AUTOSAR XML (schema 4-3-0)
package /Impl_SWC_OUTP_ARPkg
  swc implementation Impl_SWC_OUTP_type: programming-language=C, sw-version=1.0.0, vendor-id=0, behavior=SWC_OUTP_type_IB
    code-descriptors:
      code SRC: artifact-descriptors=autosar-engineering-object={short-label=EngObject, category=SWSRC}
    resource consumption ResourceConsumption
      memory section Mem_SWC_OUTP_CAL: size=0, sw-addrmethod=CAL, symbol=CAL
      memory section Mem_SWC_OUTP_CODE: size=0, sw-addrmethod=CODE, symbol=CODE
package /Impl_Type_OUTP_ARPkg
  6 x impl type:
    BOUTP_outputs: category=STRUCTURE
      1177 x element, all with category=TYPE_REFERENCE:
        VOUTP_HVTHCMSysAvail_enum: implementation-data-type=uint8
        VOUTP_LVBattVoltSta_enum: implementation-data-type=uint8
        VOUTP_VehHVPwrAvail4THCM_W: implementation-data-type=float32
        VOUTP_VehSpeed_kph: implementation-data-type=float32
        VOUTP_VehSpeedTimeOut_flg: implementation-data-type=boolean
        VOUTP_FSOffSw_enum: implementation-data-type=uint8
        VOUTP_FSOffSwTimeOut_flg: implementation-data-type=boolean
        VOUTP_ChrgPlugSta_enum: implementation-data-type=uint8
        VOUTP_PASDRMR_cm: implementation-data-type=uint8
        VOUTP_PASDRML_cm: implementation-data-type=uint8
        VOUTP_PASDRCR_cm: implementation-data-type=uint8
        VOUTP_PASDRCL_cm: implementation-data-type=uint8
        VOUTP_PASDFMR_cm: implementation-data-type=uint8
        VOUTP_PASDFML_cm: implementation-data-type=uint8
        VOUTP_PASDFCR_cm: implementation-data-type=uint8
        VOUTP_PASDFCL_cm: implementation-data-type=uint8
        VOUTP_APSDRLR_cm: implementation-data-type=uint16
        VOUTP_APSDRLL_cm: implementation-data-type=uint16
        VOUTP_APSDFLR_cm: implementation-data-type=uint16
        VOUTP_APSDFLL_cm: implementation-data-type=uint16
        VOUTP_PASAFCL_enum: implementation-data-type=uint8
        VOUTP_PASARMR_enum: implementation-data-type=uint8
        VOUTP_PASARML_enum: implementation-data-type=uint8
        VOUTP_PASARCR_enum: implementation-data-type=uint8
        VOUTP_PASARCL_enum: implementation-data-type=uint8
        VOUTP_PASAFMR_enum: implementation-data-type=uint8
        VOUTP_PASAFML_enum: implementation-data-type=uint8
        VOUTP_PASAFCR_enum: implementation-data-type=uint8
        VOUTP_USSStaRMR_flg: implementation-data-type=boolean
        VOUTP_USSStaRML_flg: implementation-data-type=boolean
        VOUTP_USSStaRLR_flg: implementation-data-type=boolean
        VOUTP_USSStaRLL_flg: implementation-data-type=boolean
        VOUTP_USSStaRCR_flg: implementation-data-type=boolean
        VOUTP_USSStaRCL_flg: implementation-data-type=boolean
        VOUTP_USSStaFMR_flg: implementation-data-type=boolean
        VOUTP_USSStaFML_flg: implementation-data-type=boolean
        VOUTP_USSStaFLR_flg: implementation-data-type=boolean
        VOUTP_USSStaFLL_flg: implementation-data-type=boolean
        VOUTP_USSStaFCR_flg: implementation-data-type=boolean
        VOUTP_USSStaFCL_flg: implementation-data-type=boolean
        VOUTP_Chime_enum: implementation-data-type=uint8
        VOUTP_SNSRLayout_enum: implementation-data-type=uint8
        VOUTP_StaFSya_flg: implementation-data-type=boolean
        VOUTP_ModOperation_enum: implementation-data-type=uint8
        VOUTP_BrkPedalPos_pct: implementation-data-type=float32
        VOUTP_BrkPedalPosTimeOut_flg: implementation-data-type=boolean
        VOUTP_LFRawWhlSpeed_kph: implementation-data-type=float32
        VOUTP_LFRawWhlSpeedTimeOut_flg: implementation-data-type=boolean
        VOUTP_RFRawWhlSpeed_kph: implementation-data-type=float32
        VOUTP_RFRawWhlSpeedTimeOut_flg: implementation-data-type=boolean
        VOUTP_LRRawWhlSpeed_kph: implementation-data-type=float32
        VOUTP_LRRawWhlSpeedTimeOut_flg: implementation-data-type=boolean
        VOUTP_RRRawWhlSpeed_kph: implementation-data-type=float32
        VOUTP_RRRawWhlSpeedTimeOut_flg: implementation-data-type=boolean
        VOUTP_LFRawWhlSpeedV_flg: implementation-data-type=boolean
        VOUTP_LFRawWhlSpeedVTimeOut_flg: implementation-data-type=boolean
        VOUTP_RFRawWhlSpeedV_flg: implementation-data-type=boolean
        VOUTP_RFRawWhlSpeedVTimeOut_flg: implementation-data-type=boolean
        VOUTP_LRRawWhlSpeedV_flg: implementation-data-type=boolean
        VOUTP_LRRawWhlSpeedVTimeOut_flg: implementation-data-type=boolean
        VOUTP_RRRawWhlSpeedV_flg: implementation-data-type=boolean
        VOUTP_RRRawWhlSpeedVTimeOut_flg: implementation-data-type=boolean
        VOUTP_LFWhlRotDir_enum: implementation-data-type=uint8
        VOUTP_LFWhlRotDirTimeOut_flg: implementation-data-type=boolean
        VOUTP_RFWhlRotDir_enum: implementation-data-type=uint8
        VOUTP_RFWhlRotDirTimeOut_flg: implementation-data-type=boolean
        VOUTP_LRWhlRotDir_enum: implementation-data-type=uint8
        VOUTP_LRWhlRotDirTimeOut_flg: implementation-data-type=boolean
        VOUTP_RRWhlRotDir_enum: implementation-data-type=uint8
        VOUTP_RRWhlRotDirTimeOut_flg: implementation-data-type=boolean
        VOUTP_LFPulseCountV_flg: implementation-data-type=boolean
        VOUTP_LFPulseCountVTimeOut_flg: implementation-data-type=boolean
        VOUTP_RFPulseCountV_flg: implementation-data-type=boolean
        VOUTP_RFPulseCountVTimeOut_flg: implementation-data-type=boolean
        VOUTP_LRPulseCountV_flg: implementation-data-type=boolean
        VOUTP_LRPulseCountVTimeOut_flg: implementation-data-type=boolean
        VOUTP_RRPulseCountV_flg: implementation-data-type=boolean
        VOUTP_RRPulseCountVTimeOut_flg: implementation-data-type=boolean
        VOUTP_LFPulseCount_enum: implementation-data-type=uint8
        VOUTP_LFPulseCountTimeOut_flg: implementation-data-type=boolean
        VOUTP_RFPulseCount_enum: implementation-data-type=uint8
        VOUTP_RFPulseCountTimeOut_flg: implementation-data-type=boolean
        VOUTP_LRPulseCount_enum: implementation-data-type=uint8
        VOUTP_LRPulseCountTimeOut_flg: implementation-data-type=boolean
        VOUTP_RRPulseCount_enum: implementation-data-type=uint8
        VOUTP_RRPulseCountTimeOut_flg: implementation-data-type=boolean
        VOUTP_ShifterHandleCmd_enum: implementation-data-type=uint8
        VOUTP_ShifterHandleCmdTimeOut_flg: implementation-data-type=boolean
        VOUTP_DriIntend_enum: implementation-data-type=uint8
        VOUTP_DriIntendTimeOut_flg: implementation-data-type=boolean
        VOUTP_EPSAOIControl_enum: implementation-data-type=uint8
        VOUTP_EPSAOIControlTimeOut_flg: implementation-data-type=boolean
        VOUTP_SASAngle_Deg: implementation-data-type=float32
        VOUTP_SASAngleTimeOut_flg: implementation-data-type=boolean
        VOUTP_SASSpeed_degps: implementation-data-type=float32
        VOUTP_SASSpeedTimeOut_flg: implementation-data-type=boolean
        VOUTP_SASSpeedValid_flg: implementation-data-type=boolean
        VOUTP_SASSpeedValidTimeOut_flg: implementation-data-type=boolean
        VOUTP_SASCAL_flg: implementation-data-type=boolean
        VOUTP_SASCALTimeOut_flg: implementation-data-type=boolean
        VOUTP_SASV_flg: implementation-data-type=boolean
        VOUTP_SASVTimeOut_flg: implementation-data-type=boolean
        VOUTP_GRADE_Deg: implementation-data-type=float32
        VOUTP_GRADETimeOut_flg: implementation-data-type=boolean
        VOUTP_YawRate_degps: implementation-data-type=float32
        VOUTP_YawRateTimeOut_flg: implementation-data-type=boolean
        VOUTP_LatAccel_Gps: implementation-data-type=float32
        VOUTP_LatAccelTimeOut_flg: implementation-data-type=boolean
        VOUTP_LongAccel_Gps: implementation-data-type=float32
        VOUTP_LongAccelTimeOut_flg: implementation-data-type=boolean
        VOUTP_MCPressure_bar: implementation-data-type=float32
        VOUTP_MCPressureTimeOut_flg: implementation-data-type=boolean
        VOUTP_YawRateV_flg: implementation-data-type=boolean
        VOUTP_YawRateVTimeOut_flg: implementation-data-type=boolean
        VOUTP_LatAccelV_flg: implementation-data-type=boolean
        VOUTP_LatAccelVTimeOut_flg: implementation-data-type=boolean
        VOUTP_LongAccelV_flg: implementation-data-type=boolean
        VOUTP_LongAccelVTimeOut_flg: implementation-data-type=boolean
        VOUTP_MCPressureV_bar: implementation-data-type=boolean
        VOUTP_MCPressureVTimeOut_flg: implementation-data-type=boolean
        VOUTP_BrkSwSta_flg: implementation-data-type=boolean
        VOUTP_BrkSwStaTimeOut_flg: implementation-data-type=boolean
        VOUTP_BrkSwV_flg: implementation-data-type=boolean
        VOUTP_BrkSwVTimeOut_flg: implementation-data-type=boolean
        VOUTP_ESCStandstill_flg: implementation-data-type=boolean
        VOUTP_ESCStandstillTimeOut_flg: implementation-data-type=boolean
        VOUTP_ESCAPSSta_enum: implementation-data-type=uint8
        VOUTP_ESCAPSStaTimeOut_flg: implementation-data-type=boolean
        VOUTP_EPBExtReleaseAvail_flg: implementation-data-type=boolean
        VOUTP_EPBExtReleaseAvailTimeOut_flg: implementation-data-type=boolean
        VOUTP_EPBExtApplyAvail_flg: implementation-data-type=boolean
        VOUTP_EPBExtApplyAvailTimeOut_flg: implementation-data-type=boolean
        VOUTP_EPBErrSta_enum: implementation-data-type=uint8
        VOUTP_EPBErrStaTimeOut_flg: implementation-data-type=boolean
        VOUTP_EPBSta_enum: implementation-data-type=uint8
        VOUTP_EPBStaTimeOut_flg: implementation-data-type=boolean
        VOUTP_AVMparkingcancel_enum: implementation-data-type=uint8
        VOUTP_AVMparkingcancelTimeOut_flg: implementation-data-type=boolean
        VOUTP_AVMparkingexcute_enum: implementation-data-type=uint8
        VOUTP_AVMparkingexcuteTimeOut_flg: implementation-data-type=boolean
        VOUTP_AVMParkingmode_enum: implementation-data-type=uint8
        VOUTP_AVMParkingmodeTimeOut_flg: implementation-data-type=boolean
        VOUTP_AVMErrSTA_flg: implementation-data-type=boolean
        VOUTP_AVMErrSTATimeOut_flg: implementation-data-type=boolean
        VOUTP_IVIStatus_flg: implementation-data-type=boolean
        VOUTP_IVIStatusTimeOut_flg: implementation-data-type=boolean
        VOUTP_CAASSw_enum: implementation-data-type=uint8
        VOUTP_CAASSwTimeOut_flg: implementation-data-type=boolean
        VOUTP_IVIScreen_enum: implementation-data-type=uint8
        VOUTP_IVIScreenTimeOut_flg: implementation-data-type=boolean
        VOUTP_ABSActive_flg: implementation-data-type=boolean
        VOUTP_ABSActiveTimeOut_flg: implementation-data-type=boolean
        VOUTP_TCSActive_flg: implementation-data-type=boolean
        VOUTP_TCSActiveTimeOut_flg: implementation-data-type=boolean
        VOUTP_DriverSeatBeltCmd_flg: implementation-data-type=boolean
        VOUTP_DriverSeatBeltCmdTimeOut_flg: implementation-data-type=boolean
        VOUTP_APSProgressPCT_pct: implementation-data-type=float32
        VOUTP_APSRQDisplay_enum: implementation-data-type=uint8
        VOUTP_APSSWVer_enum: implementation-data-type=uint8
        VOUTP_APSHWVer_enum: implementation-data-type=uint8
        VOUTP_APSExitCondition_enum: implementation-data-type=uint8
        VOUTP_APSAngleTarget_Deg: implementation-data-type=float32
        VOUTP_APSVRqEPASCtrl_flg: implementation-data-type=boolean
        VOUTP_APSRqEPASCtrl_flg: implementation-data-type=boolean
        VOUTP_CAASSta_enum: implementation-data-type=uint8
        VOUTP_DKCPDkeyAreaRAPSSta_enum: implementation-data-type=uint8
        VOUTP_DKCParkingModeCmd_enum: implementation-data-type=uint8
        VOUTP_PUIDLowPower_flg: implementation-data-type=boolean
        VOUTP_CAASVMCReqA_flg: implementation-data-type=boolean
        VOUTP_APSShiftPosnReq_enum: implementation-data-type=uint8
        VOUTP_APSSpeedCMD_kph: implementation-data-type=float32
        VOUTP_APSVMCReqA_flg: implementation-data-type=boolean
        VOUTP_RAPSBCMLamp_enum: implementation-data-type=uint8
        VOUTP_RAPSBCMLockReq_flg: implementation-data-type=boolean
        VOUTP_APSPwrReq_enum: implementation-data-type=uint8
        VOUTP_RAPSErrWarnSta_enum: implementation-data-type=uint8
        VOUTP_RAPSErrLv1_flg: implementation-data-type=boolean
        VOUTP_IVIUserTakeOverAPSSta_flg: implementation-data-type=boolean
        VOUTP_AntitheftSta_enum: implementation-data-type=uint8
        VOUTP_TailgateRemote_enum: implementation-data-type=uint8
        VOUTP_HornCtrl_flg: implementation-data-type=boolean
        VOUTP_AllDoorSW_flg: implementation-data-type=boolean
        VOUTP_BCMDoorLockSta_flg: implementation-data-type=boolean
        VOUTP_AntitheftSeatFlod_flg: implementation-data-type=boolean
        VOUTP_HoodSW_flg: implementation-data-type=boolean
        VOUTP_TailgateSW_flg: implementation-data-type=boolean
        VOUTP_DrDoorSW_flg: implementation-data-type=boolean
        VOUTP_PsDoorSW_flg: implementation-data-type=boolean
        VOUTP_RLDoorSW_flg: implementation-data-type=boolean
        VOUTP_RRDoorSW_flg: implementation-data-type=boolean
        VOUTP_LockSetting_flg: implementation-data-type=boolean
        VOUTP_FrChargingDoorCtrl_enum: implementation-data-type=uint8
        VOUTP_RrChargingDoorCtrl_enum: implementation-data-type=uint8
        VOUTP_CrashDetd_flg: implementation-data-type=boolean
        VOUTP_CTDCtrl_enum: implementation-data-type=uint8
        VOUTP_DoorLockIND_flg: implementation-data-type=boolean
        VOUTP_CTDLockSW_flg: implementation-data-type=boolean
        VOUTP_Dimmer_pct: implementation-data-type=float32
        VOUTP_DimmerEN_flg: implementation-data-type=boolean
        VOUTP_PosLamp_flg: implementation-data-type=boolean
        VOUTP_LBeam_flg: implementation-data-type=boolean
        VOUTP_HBeam_flg: implementation-data-type=boolean
        VOUTP_RrFogLamp_flg: implementation-data-type=boolean
        VOUTP_BrakeLamp_flg: implementation-data-type=boolean
        VOUTP_ReverseLamp_flg: implementation-data-type=boolean
        VOUTP_LDRL_flg: implementation-data-type=boolean
        VOUTP_RDRL_flg: implementation-data-type=boolean
        VOUTP_LBSD_flg: implementation-data-type=boolean
        VOUTP_RBSD_flg: implementation-data-type=boolean
        VOUTP_HazardSW_flg: implementation-data-type=boolean
        VOUTP_LTurnLP_flg: implementation-data-type=boolean
        VOUTP_RTurnLP_flg: implementation-data-type=boolean
        VOUTP_BCMBuzzerReq_flg: implementation-data-type=boolean
        VOUTP_MirrorCtrl_enum: implementation-data-type=uint8
        VOUTP_MirrorDefog_flg: implementation-data-type=boolean
        VOUTP_RrDefog_flg: implementation-data-type=boolean
        VOUTP_RoomLampH_flg: implementation-data-type=boolean
        VOUTP_RoomLampL_flg: implementation-data-type=boolean
        VOUTP_TrunkRel_flg: implementation-data-type=boolean
        VOUTP_TailgateHDSW_flg: implementation-data-type=boolean
        VOUTP_FrWiperL_flg: implementation-data-type=boolean
        VOUTP_FrWiperH_flg: implementation-data-type=boolean
        VOUTP_RrWiper_flg: implementation-data-type=boolean
        VOUTP_WasherCtrl_enum: implementation-data-type=uint8
        VOUTP_WiperFixMode_flg: implementation-data-type=boolean
        VOUTP_AmbLightBreath{1..6}_enum: implementation-data-type=uint8
        VOUTP_AmbLightBrightness{1..6}_enum: implementation-data-type=uint8
        VOUTP_AmbLightColor{1..6}_enum: implementation-data-type=uint8
        VOUTP_LampPwr_flg: implementation-data-type=boolean
        VOUTP_SPTGDet_flg: implementation-data-type=boolean
        VOUTP_APSOpenPTG_flg: implementation-data-type=boolean
        VOUTP_FollowMe_flg: implementation-data-type=boolean
        VOUTP_IVIRST_flg: implementation-data-type=boolean
        VOUTP_CountAlarm_enum: implementation-data-type=uint8
        VOUTP_MFSWTri_flg: implementation-data-type=boolean
        VOUTP_MirrorFlodPos_flg: implementation-data-type=boolean
        VOUTP_FuelDoorPos_flg: implementation-data-type=boolean
        VOUTP_MFRDNBrightReq_pct: implementation-data-type=uint8
        VOUTP_PTGInnerSW2_enum: implementation-data-type=uint8
        VOUTP_DrvWdwCtrlCmd_pct: implementation-data-type=uint8
        VOUTP_PasWdwCtrlCmd_pct: implementation-data-type=uint8
        VOUTP_DrRWdwCtrlCmd_pct: implementation-data-type=uint8
        VOUTP_PsRWdwCtrlCmd_pct: implementation-data-type=uint8
        VOUTP_APMDoorControlSta_flg: implementation-data-type=boolean
        VOUTP_AmbFunEN_flg: implementation-data-type=boolean
        VOUTP_AmbWelEN_flg: implementation-data-type=boolean
        VOUTP_AmbDimEN_flg: implementation-data-type=boolean
        VOUTP_AmbLinkDriSta_flg: implementation-data-type=boolean
        VOUTP_AmbPwrWarnEN_flg: implementation-data-type=boolean
        VOUTP_AmbODAEN_flg: implementation-data-type=boolean
        VOUTP_AmbColorSta_enum: implementation-data-type=uint8
        VOUTP_AmbBrightSta_enum: implementation-data-type=uint8
        VOUTP_LockAlarm_enum: implementation-data-type=uint8
        VOUTP_ATCtrl_enum: implementation-data-type=uint8
        VOUTP_fUnlockSingle_flg: implementation-data-type=boolean
        VOUTP_UserNow_enum: implementation-data-type=uint8
        VOUTP_AmbFunENFlash_enum: implementation-data-type=uint8
        VOUTP_AmbWelENFlash_enum: implementation-data-type=uint8
        VOUTP_AmbDimENFlash_enum: implementation-data-type=uint8
        VOUTP_AmbLinkDriStaFlash_enum: implementation-data-type=uint8
        VOUTP_AmbPwrWarnENFlash_enum: implementation-data-type=uint8
        VOUTP_AmbODAENFlash_enum: implementation-data-type=uint8
        VOUTP_AmbColorSta{1..5}_enum: implementation-data-type=uint8
        VOUTP_AmbColorSta7_enum: implementation-data-type=uint8
        VOUTP_AmbBrightnessSta{1..5}_enum: implementation-data-type=uint8
        VOUTP_AmbBrightnessSta7_enum: implementation-data-type=uint8
        VOUTP_HazardIND_flg: implementation-data-type=boolean
        VOUTP_DimSwSta_flg: implementation-data-type=boolean
        VOUTP_PassSWSta_flg: implementation-data-type=boolean
        VOUTP_FWipSwSta_enum: implementation-data-type=uint8
        VOUTP_FWasSwSta_enum: implementation-data-type=uint8
        VOUTP_TurnSwSta_enum: implementation-data-type=uint8
        VOUTP_TurnSwTSetSta_enum: implementation-data-type=uint8
        VOUTP_SPTGENFun_flg: implementation-data-type=boolean
        VOUTP_SPTGENFunMem_enum: implementation-data-type=uint8
        VOUTP_OutMode_enum: implementation-data-type=uint8
        VOUTP_TurnSwTimeSetSta123_enum: implementation-data-type=uint8
        VOUTP_TurnSwTimeSetSta457_enum: implementation-data-type=uint8
        VOUTP_FDLHandleLampCmd_flg: implementation-data-type=boolean
        VOUTP_FDRHandleLampCmd_flg: implementation-data-type=boolean
        VOUTP_FDHandleCmd_enum: implementation-data-type=uint8
        VOUTP_HBeamADB_enum: implementation-data-type=uint8
        VOUTP_WalkInUnLkENMem_enum: implementation-data-type=uint8
        VOUTP_WalkOutLkENMem_enum: implementation-data-type=uint8
        VOUTP_RmLpModeENMem_enum: implementation-data-type=uint8
        VOUTP_LockSettingStaMem_enum: implementation-data-type=uint8
        VOUTP_FollowMeENMem_enum: implementation-data-type=uint8
        VOUTP_WalkInUnLkENFunSta_flg: implementation-data-type=boolean
        VOUTP_WalkOutLkENFunSta_flg: implementation-data-type=boolean
        VOUTP_RmLpModeENFunSta_flg: implementation-data-type=boolean
        VOUTP_FollowMeENFunSta_flg: implementation-data-type=boolean
        VOUTP_HoodRelCmd_flg: implementation-data-type=boolean
        VOUTP_WelcomeLight_enum: implementation-data-type=uint8
        VOUTP_PTGOpenHeightSta_enum: implementation-data-type=uint8
        VOUTP_UserHeightSet_cnt: implementation-data-type=uint16
        VOUTP_PTGUserHeight{1..5}_cnt: implementation-data-type=uint16
        VOUTP_PTGUserHeight7_cnt: implementation-data-type=uint16
        VOUTP_PTGOpenHeight12_enum: implementation-data-type=uint8
        VOUTP_PTGOpenHeight34_enum: implementation-data-type=uint8
        VOUTP_PTGOpenHeight57_enum: implementation-data-type=uint8
        VOUTP_SenstivityPosnCmd_enum: implementation-data-type=uint8
        VOUTP_TimeGapLevelSta_enum: implementation-data-type=uint8
        VOUTP_ACCLevelMem12_enum: implementation-data-type=uint8
        VOUTP_ACCLevelMem34_enum: implementation-data-type=uint8
        VOUTP_ACCLevelMem57_enum: implementation-data-type=uint8
        VOUTP_LRightStaCmd_flg: implementation-data-type=boolean
        VOUTP_LLeftStaCmd_flg: implementation-data-type=boolean
        VOUTP_AutoLockSta_flg: implementation-data-type=boolean
        VOUTP_AutoLockMem_enum: implementation-data-type=uint8
        VOUTP_AutoUnlockSta_flg: implementation-data-type=boolean
        VOUTP_AutoUnlockMem_enum: implementation-data-type=uint8
        VOUTP_HMIKey{1..8}FuncSta_enum: implementation-data-type=uint8
        VOUTP_AutoWipHSpdENSta_flg: implementation-data-type=boolean
        VOUTP_DrvWdwReqAP_enum: implementation-data-type=uint8
        VOUTP_PasWdwReqAP_enum: implementation-data-type=uint8
        VOUTP_DrRWdwReqAP_enum: implementation-data-type=uint8
        VOUTP_PsRWdwReqAP_enum: implementation-data-type=uint8
        VOUTP_CLWinLockDrSta_flg: implementation-data-type=boolean
        VOUTP_CLWinLockDrStaMem_enum: implementation-data-type=uint8
        VOUTP_WinLFOpenedSta_pct: implementation-data-type=uint8
        VOUTP_WinRFOpenedSta_pct: implementation-data-type=uint8
        VOUTP_WinLROpenedSta_pct: implementation-data-type=uint8
        VOUTP_WinRROpenedSta_pct: implementation-data-type=uint8
        VOUTP_C3BMS6RCDTC_raw32: implementation-data-type=uint32
        VOUTP_C3BMS6CSDTC_raw32: implementation-data-type=uint32
        VOUTP_C3BMS6LCDTC_raw32: implementation-data-type=uint32
        VOUTP_C3BMS1RCDTC_raw32: implementation-data-type=uint32
        VOUTP_C3BMS1CSDTC_raw32: implementation-data-type=uint32
        VOUTP_C3BMS1LCDTC_raw32: implementation-data-type=uint32
        VOUTP_C3CCU1RCDTC_raw32: implementation-data-type=uint32
        VOUTP_C3CCU1CSDTC_raw32: implementation-data-type=uint32
        VOUTP_C3CCU1LCDTC_raw32: implementation-data-type=uint32
        VOUTP_C3CCU2RCDTC_raw32: implementation-data-type=uint32
        VOUTP_C3CCU2CSDTC_raw32: implementation-data-type=uint32
        VOUTP_C3CCU2LCDTC_raw32: implementation-data-type=uint32
        VOUTP_C1ABM1RCDTC_raw32: implementation-data-type=uint32
        VOUTP_C1ABM1CSDTC_raw32: implementation-data-type=uint32
        VOUTP_C1ABM1LCDTC_raw32: implementation-data-type=uint32
        VOUTP_Lv{1..4}ErrDTC_raw32: implementation-data-type=uint32
        VOUTP_BrkSWErrDTC_raw32: implementation-data-type=uint32
        VOUTP_BrkSWNoBacDTC_raw32: implementation-data-type=uint32
        VOUTP_KeyAuthDTC_raw32: implementation-data-type=uint32
        VOUTP_ONtoRdyDTC_raw32: implementation-data-type=uint32
        VOUTP_HVB4PreDTC_raw32: implementation-data-type=uint32
        VOUTP_MCU4PreDTC_raw32: implementation-data-type=uint32
        VOUTP_DCDC4PreDTC_raw32: implementation-data-type=uint32
        VOUTP_HVRlyCloDTC_raw32: implementation-data-type=uint32
        VOUTP_BMSRdyDTC_raw32: implementation-data-type=uint32
        VOUTP_DCDCEnaDTC_raw32: implementation-data-type=uint32
        VOUTP_HiLvSaChkDTC_raw32: implementation-data-type=uint32
        VOUTP_MidLvSaChkDTC_raw32: implementation-data-type=uint32
        VOUTP_MCUDisDTC_raw32: implementation-data-type=uint32
        VOUTP_DCDCDisDTC_raw32: implementation-data-type=uint32
        VOUTP_HVRlyOpDTC_raw32: implementation-data-type=uint32
        VOUTP_MCUActDTC_raw32: implementation-data-type=uint32
        VOUTP_OBC4PreDTC_raw32: implementation-data-type=uint32
        VOUTP_IniLVLoDTC_raw32: implementation-data-type=uint32
        VOUTP_LVSupLoDTC_raw32: implementation-data-type=uint32
        VOUTP_LVSupHiDTC_raw32: implementation-data-type=uint32
        VOUTP_DrStSWDTC_raw32: implementation-data-type=uint32
        VOUTP_FLDoorSWDTC_raw32: implementation-data-type=uint32
        VOUTP_RLDoorSWDTC_raw32: implementation-data-type=uint32
        VOUTP_FRDoorSWDTC_raw32: implementation-data-type=uint32
        VOUTP_RRDoorSWDTC_raw32: implementation-data-type=uint32
        VOUTP_HoodSWDTC_raw32: implementation-data-type=uint32
        VOUTP_TailgaSWDTC_raw32: implementation-data-type=uint32
        VOUTP_EDriveSysErrVCUErr_flg: implementation-data-type=boolean
        VOUTP_VehMalfunLevel_enum: implementation-data-type=uint8
        VOUTP_APS1SigOoRDTC_raw32: implementation-data-type=uint32
        VOUTP_APS2SigOoRDTC_raw32: implementation-data-type=uint32
        VOUTP_APSCorrErrDTC_raw32: implementation-data-type=uint32
        VOUTP_MCUF1NoComDTC_raw32: implementation-data-type=uint32
        VOUTP_MCUR1NoComDTC_raw32: implementation-data-type=uint32
        VOUTP_Shifter1NoComDTC_raw32: implementation-data-type=uint32
        VOUTP_ESC7NoComDTC_raw32: implementation-data-type=uint32
        VOUTP_ESC1NoComDTC_raw32: implementation-data-type=uint32
        VOUTP_ESC5NoComDTC_raw32: implementation-data-type=uint32
        VOUTP_EnterNewOperCyc_flg: implementation-data-type=boolean
        VOUTP_DiagHCrashDTC_raw32: implementation-data-type=uint32
        VOUTP_DiagFLTSDTC_raw32: implementation-data-type=uint32
        VOUTP_DiagFRTSDTC_raw32: implementation-data-type=uint32
        VOUTP_DiagRLTSDTC_raw32: implementation-data-type=uint32
        VOUTP_DiagRRTSDTC_raw32: implementation-data-type=uint32
        VOUTP_FCLUSSDTC_raw32: implementation-data-type=uint32
        VOUTP_FMLUSSDTC_raw32: implementation-data-type=uint32
        VOUTP_FMRUSSDTC_raw32: implementation-data-type=uint32
        VOUTP_FCRUSSDTC_raw32: implementation-data-type=uint32
        VOUTP_RCLUSSDTC_raw32: implementation-data-type=uint32
        VOUTP_RMLUSSDTC_raw32: implementation-data-type=uint32
        VOUTP_RMRUSSDTC_raw32: implementation-data-type=uint32
        VOUTP_RCRUSSDTC_raw32: implementation-data-type=uint32
        VOUTP_FLLUSSDTC_raw32: implementation-data-type=uint32
        VOUTP_FLRUSSDTC_raw32: implementation-data-type=uint32
        VOUTP_RLLUSSDTC_raw32: implementation-data-type=uint32
        VOUTP_RLRUSSDTC_raw32: implementation-data-type=uint32
        VOUTP_FCM2NoComDTC_raw32: implementation-data-type=uint32
        VOUTP_FCM2RCErrDTC_raw32: implementation-data-type=uint32
        VOUTP_FCM2CSErrDTC_raw32: implementation-data-type=uint32
        VOUTP_FCM3NoComDTC_raw32: implementation-data-type=uint32
        VOUTP_FCM3RCErrDTC_raw32: implementation-data-type=uint32
        VOUTP_FCM3CSErrDTC_raw32: implementation-data-type=uint32
        VOUTP_FCM4NoComDTC_raw32: implementation-data-type=uint32
        VOUTP_FCM4CSErrDTC_raw32: implementation-data-type=uint32
        VOUTP_FCM5NoComDTC_raw32: implementation-data-type=uint32
        VOUTP_FCM5CSErrDTC_raw32: implementation-data-type=uint32
        VOUTP_ZoneSCPNoComDTC_raw32: implementation-data-type=uint32
        VOUTP_BMSSigErrDetDTC_raw32: implementation-data-type=uint32
        VOUTP_FCMACCSigErrDetDTC_raw32: implementation-data-type=uint32
        VOUTP_FrMCUSigErrDetDTC_raw32: implementation-data-type=uint32
        VOUTP_RrMCUSigErrDetDTC_raw32: implementation-data-type=uint32
        VOUTP_CCUSigErrDetDTC_raw32: implementation-data-type=uint32
        VOUTP_ACCAccelCmdErrDetDTC_raw32: implementation-data-type=uint32
        VOUTP_ACCMalfuncDetDTC_raw32: implementation-data-type=uint32
        VOUTP_CCMalfuncDetDTC_raw32: implementation-data-type=uint32
        VOUTP_MSAMalfuncDetDTC_raw32: implementation-data-type=uint32
        VOUTP_ISAMalfuncDetDTC_raw32: implementation-data-type=uint32
        VOUTP_MCUF1RCErrDTC_raw32: implementation-data-type=uint32
        VOUTP_MCUR1RCErrDTC_raw32: implementation-data-type=uint32
        VOUTP_MCUF1CSErrDTC_raw32: implementation-data-type=uint32
        VOUTP_MCUR1CSErrDTC_raw32: implementation-data-type=uint32
        VOUTP_Shifter1RCErrDTC_raw32: implementation-data-type=uint32
        VOUTP_Shifter1CSErrDTC_raw32: implementation-data-type=uint32
        VOUTP_ESC7RCErrDTC_raw32: implementation-data-type=uint32
        VOUTP_ESC7CSErrDTC_raw32: implementation-data-type=uint32
        VOUTP_ESC1RCErrDTC_raw32: implementation-data-type=uint32
        VOUTP_ESC1CSErrDTC_raw32: implementation-data-type=uint32
        VOUTP_ESC5RCErrDTC_raw32: implementation-data-type=uint32
        VOUTP_ESC5CSErrDTC_raw32: implementation-data-type=uint32
        VOUTP_FrMCUTqErrDTC_raw32: implementation-data-type=uint32
        VOUTP_RrMCUTqErrDTC_raw32: implementation-data-type=uint32
        VOUTP_LFBatwarnDTC_raw32: implementation-data-type=uint32
        VOUTP_RFBatwarnDTC_raw32: implementation-data-type=uint32
        VOUTP_LRBatwarnDTC_raw32: implementation-data-type=uint32
        VOUTP_RRBatwarnDTC_raw32: implementation-data-type=uint32
        VOUTP_LFPressIndiDTC_raw32: implementation-data-type=uint32
        VOUTP_RFPressIndiDTC_raw32: implementation-data-type=uint32
        VOUTP_LRPressIndiDTC_raw32: implementation-data-type=uint32
        VOUTP_RRPressIndiDTC_raw32: implementation-data-type=uint32
        VOUTP_LFWheelTmpHighDTC_raw32: implementation-data-type=uint32
        VOUTP_RFWheelTmpHighDTC_raw32: implementation-data-type=uint32
        VOUTP_LRWheelTmpHighDTC_raw32: implementation-data-type=uint32
        VOUTP_RRWheelTmpHighDTC_raw32: implementation-data-type=uint32
        VOUTP_LFSensorFailDTC_raw32: implementation-data-type=uint32
        VOUTP_RFSensorFailDTC_raw32: implementation-data-type=uint32
        VOUTP_LRSensorFailDTC_raw32: implementation-data-type=uint32
        VOUTP_RRSensorFailDTC_raw32: implementation-data-type=uint32
        VOUTP_C1EPAS2LCDTC_raw32: implementation-data-type=uint32
        VOUTP_5vAPS1PwrErrDTC_raw32: implementation-data-type=uint32
        VOUTP_5vAPS2PwrErrDTC_raw32: implementation-data-type=uint32
        VOUTP_EPBLockTODTC_raw32: implementation-data-type=uint32
        VOUTP_EPBUnlockTODTC_raw32: implementation-data-type=uint32
        VOUTP_LimpHomeAct_flg: implementation-data-type=boolean
        VOUTP_DTCDetect_enum: implementation-data-type=uint8
        VOUTP_EngagePFail_flg: implementation-data-type=boolean
        VOUTP_DisengagePFail_flg: implementation-data-type=boolean
        VOUTP_VCURAPSErrLv2_flg: implementation-data-type=boolean
        VOUTP_VCURAPSErrLv3_flg: implementation-data-type=boolean
        VOUTP_EDriveSysErrShifterErr_flg: implementation-data-type=boolean
        VOUTP_LVSysErrPwrOutErr_flg: implementation-data-type=boolean
        VOUTP_HVRlyOpFail_flg: implementation-data-type=boolean
        VOUTP_MCUActDisFail_flg: implementation-data-type=boolean
        VOUTP_VCUBrkSWSta_enum: implementation-data-type=uint8
        VOUTP_VCUFLDoorSta_flg: implementation-data-type=boolean
        VOUTP_VCUFRDoorSta_flg: implementation-data-type=boolean
        VOUTP_VCURLDoorSta_flg: implementation-data-type=boolean
        VOUTP_VCURRDoorSta_flg: implementation-data-type=boolean
        VOUTP_SysAllowReadySta_flg: implementation-data-type=boolean
        VOUTP_VCUHoodSWSta_flg: implementation-data-type=boolean
        VOUTP_VCUTailgateSWSta_flg: implementation-data-type=boolean
        VOUTP_CAN{1..6}BusErrorDTC_raw32: implementation-data-type=uint32
        VOUTP_FrMCU4PreDTC_raw32: implementation-data-type=uint32
        VOUTP_FrMCUDisDTC_raw32: implementation-data-type=uint32
        VOUTP_FrMCUActDTC_raw32: implementation-data-type=uint32
        VOUTP_RegenErrDTC_raw32: implementation-data-type=uint32
        VOUTP_ActAPSPosn_pct: implementation-data-type=float32
        VOUTP_LowIdleAccPedal_flg: implementation-data-type=boolean
        VOUTP_EAPS1MIN_pct: implementation-data-type=float32
        VOUTP_EAPS2MIN_pct: implementation-data-type=float32
        VOUTP_ResetPedalZeroPosStart_flg: implementation-data-type=boolean
        VOUTP_EAPS1NRM_pct: implementation-data-type=float32
        VOUTP_EAPS2NRM_pct: implementation-data-type=float32
        VOUTP_EAPS1RAW_pct: implementation-data-type=float32
        VOUTP_EAPS2RAW_pct: implementation-data-type=float32
        VOUTP_VSS_kph: implementation-data-type=float32
        VOUTP_RUNTM_s: implementation-data-type=uint16
        VOUTP_MILDIST_km: implementation-data-type=float32
        VOUTP_CLRDIST_km: implementation-data-type=float32
        VOUTP_APPD_pct: implementation-data-type=float32
        VOUTP_APPE_pct: implementation-data-type=float32
        VOUTP_ODOMETER_km: implementation-data-type=float32
        VOUTP_NUMPSATRIPSFLTMEMCLR_cnt: implementation-data-type=uint16
        VOUTP_PSAR_sec: implementation-data-type=uint32
        VOUTP_PSAL_sec: implementation-data-type=uint32
        VOUTP_IPSAR_sec: implementation-data-type=uint32
        VOUTP_IPSAL_sec: implementation-data-type=uint32
        VOUTP_CPSAR_sec: implementation-data-type=uint32
        VOUTP_CPSAL_sec: implementation-data-type=uint32
        VOUTP_PKER_kphsqr: implementation-data-type=float32
        VOUTP_PKEL_kphsqr: implementation-data-type=float32
        VOUTP_ResetCDEODTR_km: implementation-data-type=float32
        VOUTP_CDEODTR_km: implementation-data-type=float32
        VOUTP_CDEODTL_km: implementation-data-type=float32
        VOUTP_QTYPSATRIPSR_cnt: implementation-data-type=uint32
        VOUTP_QTYPSATRIPSL_cnt: implementation-data-type=uint32
        VOUTP_PROTOCOLID_enum: implementation-data-type=uint8
        VOUTP_CALID_cnt: implementation-data-type=u8_Array16_type
        VOUTP_ECUNAME_cnt: implementation-data-type=u8_Array20_type
        VOUTP_PKERNumerator_kphsqr: implementation-data-type=float32
        VOUTP_PKELNumerator_kphsqr: implementation-data-type=float32
        VOUTP_VinCode_cnt: implementation-data-type=u8_Array17_type
        VOUTP_DIDModelVersion_raw: implementation-data-type=uint8
        VOUTP_DIDModelVersionChksum_raw: implementation-data-type=uint8
        VOUTP_DKCTimeSN_cnt: implementation-data-type=uint32
        VOUTP_DKCAuthSta_enum: implementation-data-type=uint8
        VOUTP_TimeSNDKCFbk_cnt: implementation-data-type=uint32
        VOUTP_PCommandToBCM_enum: implementation-data-type=uint8
        VOUTP_KeyAreaLockUnlock_enum: implementation-data-type=uint8
        VOUTP_KeyMissSta_flg: implementation-data-type=boolean
        VOUTP_ShippingMode_flg: implementation-data-type=boolean
        VOUTP_KeyNumSta_enum: implementation-data-type=uint8
        VOUTP_DkeyShowIVISta_enum: implementation-data-type=uint8
        VOUTP_DkeyAreaRAPSSta_enum: implementation-data-type=uint8
        VOUTP_KeyAreaPS_enum: implementation-data-type=uint8
        VOUTP_KeyAreaSPTGSta_enum: implementation-data-type=uint8
        VOUTP_KeyAreaPTG_enum: implementation-data-type=uint8
        VOUTP_UWB4Invalid_flg: implementation-data-type=uint8
        VOUTP_UWBOnOff_flg: implementation-data-type=boolean
        VOUTP_UWB3Invalid_flg: implementation-data-type=uint8
        VOUTP_UWB1Invalid_flg: implementation-data-type=uint8
        VOUTP_UWB2Invalid_flg: implementation-data-type=uint8
        VOUTP_UWB0Invalid_flg: implementation-data-type=uint8
        VOUTP_UIDBatVolt_enum: implementation-data-type=uint16
        VOUTP_CoordinateX_enum: implementation-data-type=sint16
        VOUTP_FDCSPTGDet_flg: implementation-data-type=boolean
        VOUTP_FDCSPTGOpen_flg: implementation-data-type=boolean
        VOUTP_UIDLowPowerSta_flg: implementation-data-type=boolean
        VOUTP_CoordinateY_enum: implementation-data-type=sint16
        VOUTP_AllowSleep_flg: implementation-data-type=boolean
        VOUTP_KeyTypeSta_enum: implementation-data-type=uint8
        VOUTP_CalDistance_enum: implementation-data-type=uint8
        VOUTP_UWBDetPTGArea_enum: implementation-data-type=uint8
        VOUTP_A0UWBEvent_enum: implementation-data-type=uint8
        VOUTP_ParkingModeCmd_enum: implementation-data-type=uint8
        VOUTP_KeyModeSta_enum: implementation-data-type=uint8
        VOUTP_ReVehData_enum: implementation-data-type=uint8
        VOUTP_UWB0Distance_enum: implementation-data-type=uint16
        VOUTP_DKeyWelcomeSta_enum: implementation-data-type=uint8
        VOUTP_UWB{1..4}Distance_enum: implementation-data-type=uint16
        VOUTP_BLERSSI_enum: implementation-data-type=uint8
        VOUTP_BLEdcEvent_enum: implementation-data-type=uint8
        VOUTP_UWB{0..4}FPP_enum: implementation-data-type=sint16
        VOUTP_UWBDetArea_enum: implementation-data-type=uint8
        VOUTP_OutputPCMDModule_enum: implementation-data-type=uint8
        VOUTP_FDCDKCAllowSleep_flg: implementation-data-type=boolean
        VOUTP_JudgeKeepUnlockZone_flg: implementation-data-type=boolean
        VOUTP_DISCTurn_flg: implementation-data-type=boolean
        VOUTP_DISCTargetSpd_kph: implementation-data-type=float32
        VOUTP_DISCSta_enum: implementation-data-type=uint8
        VOUTP_DISCButtSta_flg: implementation-data-type=boolean
        VOUTP_AllCANTxReq_flg: implementation-data-type=boolean
        VOUTP_NMmTxReq_flg: implementation-data-type=boolean
        VOUTP_Awake_enum: implementation-data-type=uint8
        VOUTP_CSB_flg: implementation-data-type=boolean
        VOUTP_ErrorState_enum: implementation-data-type=uint8
        VOUTP_NodeID_enum: implementation-data-type=uint8
        VOUTP_PNI_flg: implementation-data-type=boolean
        VOUTP_RptMsgReq_flg: implementation-data-type=boolean
        VOUTP_WakeUp_enum: implementation-data-type=uint8
        VOUTP_ActiveWU_flg: implementation-data-type=boolean
        VOUTP_SysNMmSta_enum: implementation-data-type=uint8
        VOUTP_NetworkReq_flg: implementation-data-type=boolean
        VOUTP_PowerUpState_enum: implementation-data-type=uint8
        VOUTP_PowerDownState_enum: implementation-data-type=uint8
        VOUTP_PowerUpFault_enum: implementation-data-type=uint8
        VOUTP_PowerDownFault_enum: implementation-data-type=uint8
        VOUTP_ActiveDischargeReq_flg: implementation-data-type=boolean
        VOUTP_DCDCEnaReq_flg: implementation-data-type=boolean
        VOUTP_DCDCVoltSetpoint_V: implementation-data-type=float32
        VOUTP_HVBatCnctReq_flg: implementation-data-type=boolean
        VOUTP_HVSysReadyToCharge_enum: implementation-data-type=uint8
        VOUTP_PowerSta_enum: implementation-data-type=uint8
        VOUTP_LVPwrSta_flg: implementation-data-type=boolean
        VOUTP_HVPwrSta_flg: implementation-data-type=boolean
        VOUTP_SysPowerMode_enum: implementation-data-type=uint8
        VOUTP_FrMCUEnaReq_flg: implementation-data-type=boolean
        VOUTP_RrMCUEnaReq_flg: implementation-data-type=boolean
        VOUTP_DrivetrainSelect_enum: implementation-data-type=uint8
        VOUTP_DrSeatSta_enum: implementation-data-type=uint8
        VOUTP_PwrStaSelect_enum: implementation-data-type=uint8
        VOUTP_PwrStaConstraint_enum: implementation-data-type=uint8
        VOUTP_TCountSta_enum: implementation-data-type=uint8
        VOUTP_PwrUpReq_enum: implementation-data-type=uint8
        VOUTP_PwrDownReq_enum: implementation-data-type=uint8
        VOUTP_LowSOCWarn_enum: implementation-data-type=uint8
        VOUTP_ReVehThdChkSta_enum: implementation-data-type=uint8
        VOUTP_EvccAplusPwrUpReq_flg: implementation-data-type=boolean
        VOUTP_PwrStaONTOPopReq_flg: implementation-data-type=boolean
        VOUTP_IVIPwrStaONTOPopT_s: implementation-data-type=float32
        VOUTP_LVChrgHoldTtimer_s: implementation-data-type=float32
        VOUTP_LVBattChrgTimeCnt_s: implementation-data-type=float32
        VOUTP_SilentChkAllowSleep_flg: implementation-data-type=boolean
        VOUTP_TimerAllowSleep_flg: implementation-data-type=boolean
        VOUTP_FDADC12VDetAvg_mV: implementation-data-type=float32
        VOUTP_PMMAllowECUSleep_flg: implementation-data-type=boolean
        VOUTP_LVSilentChrgSta_enum: implementation-data-type=uint8
        VOUTP_LVSilentChrgReq_flg: implementation-data-type=boolean
        VOUTP_LVSilentChrgLv_enum: implementation-data-type=uint8
        VOUTP_CtrlFrPwrStbA1P_flg: implementation-data-type=boolean
        VOUTP_CtrlFrRC1_flg: implementation-data-type=boolean
        VOUTP_CtrlFrBMSCCUCIR_flg: implementation-data-type=boolean
        VOUTP_CtrlFrEDUINVERTER_flg: implementation-data-type=boolean
        VOUTP_HWResetSta_enum: implementation-data-type=uint8
        VOUTP_CtrlDrPwrStbA2_flg: implementation-data-type=boolean
        VOUTP_PwrStaTOSta_enum: implementation-data-type=uint8
        VOUTP_Sched_ChgTOSta_enum: implementation-data-type=uint8
        VOUTP_PwrReq_OTA_enum: implementation-data-type=uint8
        VOUTP_OTAPwrReqOFFChkSta_enum: implementation-data-type=uint8
        VOUTP_OTAPwrReqStdChkSta_enum: implementation-data-type=uint8
        VOUTP_PwrReqRAPSAvail_flg: implementation-data-type=boolean
        VOUTP_HWVer{1..3}_cnt: implementation-data-type=uint8
        VOUTP_CarModel{1..3}_cnt: implementation-data-type=uint8
        VOUTP_ECU1_cnt: implementation-data-type=uint8
        VOUTP_ECU2_cnt: implementation-data-type=uint8
        VOUTP_Major1_cnt: implementation-data-type=uint8
        VOUTP_Major2_cnt: implementation-data-type=uint8
        VOUTP_Minor1_cnt: implementation-data-type=uint8
        VOUTP_Minor2_cnt: implementation-data-type=uint8
        VOUTP_Patch1_cnt: implementation-data-type=uint8
        VOUTP_Patch2_cnt: implementation-data-type=uint8
        VOUTP_Country1_cnt: implementation-data-type=uint8
        VOUTP_Country2_cnt: implementation-data-type=uint8
        VOUTP_Variation_cnt: implementation-data-type=uint8
        VOUTP_Dash1_cnt: implementation-data-type=uint8
        VOUTP_Change1_cnt: implementation-data-type=uint8
        VOUTP_Change2_cnt: implementation-data-type=uint8
        VOUTP_Dash2_cnt: implementation-data-type=uint8
        VOUTP_SHA{1..8}_cnt: implementation-data-type=uint8
        VOUTP_NvWriteReqRisingEdge_flg: implementation-data-type=boolean
        VOUTP_FdcSlpReqRisingEdge_flg: implementation-data-type=boolean
        VOUTP_FdcSlpTime_sec: implementation-data-type=float32
        VOUTP_PmicBootReason_enum: implementation-data-type=uint8
        VOUTP_WisrBootReason_raw32: implementation-data-type=uint32
        VOUTP_AcoreRebootCmdACK_flg: implementation-data-type=boolean
        VOUTP_CurrentNmState_enum: implementation-data-type=uint8
        VOUTP_ECUGen1_cnt: implementation-data-type=uint8
        VOUTP_ECUGen2_cnt: implementation-data-type=uint8
        VOUTP_PmicBootPath_raw32: implementation-data-type=uint32
        VOUTP_DrivingMode_cnt: implementation-data-type=uint8
        VOUTP_ModelYear_cnt: implementation-data-type=uint8
        VOUTP_Var4_cnt: implementation-data-type=uint8
        VOUTP_Var5_cnt: implementation-data-type=uint8
        VOUTP_FDCompCmd_rpm: implementation-data-type=uint16
        VOUTP_FDSOV{1..3}Cmd_flg: implementation-data-type=boolean
        VOUTP_FDEXV1Cmd_step: implementation-data-type=uint16
        VOUTP_FDEXV2Cmd_step: implementation-data-type=uint16
        VOUTP_FDSOTXVCmd_flg: implementation-data-type=boolean
        VOUTP_FDFWVCmd_flg: implementation-data-type=boolean
        VOUTP_FDTWVCmd_pct: implementation-data-type=float32
        VOUTP_FDFrWPTCHeatPwrCmd_W: implementation-data-type=float32
        VOUTP_CoolgFanActDuty_pct: implementation-data-type=float32
        VOUTP_FDAGSCmd_enum: implementation-data-type=uint8
        VOUTP_FDEWP{1..3}Cmd_enum: implementation-data-type=uint8
        VOUTP_FDFrLeAPTCHeatPwrCmd_W: implementation-data-type=float32
        VOUTP_FDFrRiAPTCHeatPwrCmd_W: implementation-data-type=float32
        VOUTP_FDRrAPTCHeatPwrCmd_W: implementation-data-type=float32
        VOUTP_FDBlowerCmd_pct: implementation-data-type=float32
        VOUTP_BatteryMode_enum: implementation-data-type=uint8
        VOUTP_EDriveMode_enum: implementation-data-type=uint8
        VOUTP_CabinMode_enum: implementation-data-type=uint8
        VOUTP_CCUACLampSts_flg: implementation-data-type=boolean
        VOUTP_CCUAutoLampSts_flg: implementation-data-type=boolean
        VOUTP_CCUACMaxLampSts_flg: implementation-data-type=boolean
        VOUTP_CCUSyncLampSts_flg: implementation-data-type=boolean
        VOUTP_sigAirIntenZon1St_enum: implementation-data-type=uint8
        VOUTP_sigWindDirZon1St_enum: implementation-data-type=uint8
        VOUTP_sigRecircSt_flg: implementation-data-type=boolean
        VOUTP_sigSetTempZon1St_C: implementation-data-type=float32
        VOUTP_sigSetTempZon2St_C: implementation-data-type=float32
        VOUTP_sigClntTHvBattOut_C: implementation-data-type=float32
        VOUTP_sigCbnSolarLeft_W: implementation-data-type=float32
        VOUTP_sigClntTHvBattIn_C: implementation-data-type=float32
        VOUTP_sigCbnSolarRight_W: implementation-data-type=float32
        VOUTP_sigAmbAirT_C: implementation-data-type=float32
        VOUTP_sigCbnAirT_C: implementation-data-type=float32
        VOUTP_ACSubMode_enum: implementation-data-type=uint8
        VOUTP_FDRecyAutoCmd_enum: implementation-data-type=uint8
        VOUTP_ACModeMem_enum: implementation-data-type=uint8
        VOUTP_Face_flg: implementation-data-type=boolean
        VOUTP_Foot_flg: implementation-data-type=boolean
        VOUTP_Frost_flg: implementation-data-type=boolean
        VOUTP_FaceM_flg: implementation-data-type=boolean
        VOUTP_FootM_flg: implementation-data-type=boolean
        VOUTP_CCUSyncSts_flg: implementation-data-type=boolean
        VOUTP_ACForceOFF_flg: implementation-data-type=boolean
        VOUTP_RecAutoFlg_flg: implementation-data-type=boolean
        VOUTP_AirIntenZone1M_enum: implementation-data-type=uint8
        VOUTP_fdefog_flg: implementation-data-type=boolean
        VOUTP_sigSetTempZon2StM_C: implementation-data-type=float32
        VOUTP_sigDfrstSt_flg: implementation-data-type=boolean
        VOUTP_FDCTHCAirIntZ3Sta_enum: implementation-data-type=uint8
        VOUTP_FDCTHCLEVentModeSta_enum: implementation-data-type=uint8
        VOUTP_FDCTHCREVentModeSta_enum: implementation-data-type=uint8
        VOUTP_FDCTHCLEVentZSta_enum: implementation-data-type=uint8
        VOUTP_FDCTHCCLEVentZSta_enum: implementation-data-type=uint8
        VOUTP_FDCTHCREVentZSta_enum: implementation-data-type=uint8
        VOUTP_FDCTHCCREVentZSta_enum: implementation-data-type=uint8
        VOUTP_FDCTHCLEVentYSta_enum: implementation-data-type=uint8
        VOUTP_FDCTHCLVentENSta_flg: implementation-data-type=boolean
        VOUTP_FDCTHCCLEVentYSta_enum: implementation-data-type=uint8
        VOUTP_FDCTHCCLVentENSta_flg: implementation-data-type=boolean
        VOUTP_FDCTHCREVentYSta_enum: implementation-data-type=uint8
        VOUTP_FDCTHCRVentENSta_flg: implementation-data-type=boolean
        VOUTP_FDCTHCCREVentYSta_enum: implementation-data-type=uint8
        VOUTP_FDCTHCCRVentENSta_flg: implementation-data-type=boolean
        VOUTP_FDCTHCMAPTCForceOFFSta_flg: implementation-data-type=boolean
        VOUTP_FDCFGSAirIntSta_enum: implementation-data-type=uint8
        VOUTP_FDCFGSChSta_enum: implementation-data-type=uint8
        VOUTP_FDCFGSAirIntCmd_enum: implementation-data-type=uint8
        VOUTP_FDCFGSFuncSta_enum: implementation-data-type=uint8
        VOUTP_FDCFGSChCmd_enum: implementation-data-type=uint8
        VOUTP_FDCFGSIONSWSta_flg: implementation-data-type=boolean
        VOUTP_FDCFGSIONCmd_flg: implementation-data-type=boolean
        VOUTP_FDCTHCMPreWPTCHeatSta_enum: implementation-data-type=uint8
        VOUTP_EWPBUflag{1..3}_flg: implementation-data-type=boolean
        VOUTP_FaceMSet_enum: implementation-data-type=uint8
        VOUTP_FootMSet_enum: implementation-data-type=uint8
        VOUTP_fdefogSet_enum: implementation-data-type=uint8
        VOUTP_CCUSyncStsSet_enum: implementation-data-type=uint8
        VOUTP_sigRecircStSet_enum: implementation-data-type=uint8
        VOUTP_RecyAutoSet_enum: implementation-data-type=uint8
        VOUTP_AirIntenZone1MSet{1..5}_enum: implementation-data-type=uint8
        VOUTP_AirIntenZone1MSet7_enum: implementation-data-type=uint8
        VOUTP_AirIntenZone3MSet{1..5}_enum: implementation-data-type=uint8
        VOUTP_AirIntenZone3MSet7_enum: implementation-data-type=uint8
        VOUTP_IONSWStaSet_enum: implementation-data-type=uint8
        VOUTP_FDCFGSChStaSet123_enum: implementation-data-type=uint8
        VOUTP_FDCFGSChStaSet457_enum: implementation-data-type=uint8
        VOUTP_FDCFGSAirIntStaSet123_enum: implementation-data-type=uint8
        VOUTP_FDCFGSAirIntStaSet457_enum: implementation-data-type=uint8
        VOUTP_LVentENSet_enum: implementation-data-type=uint8
        VOUTP_CLVentENSet_enum: implementation-data-type=uint8
        VOUTP_RVentENSet_enum: implementation-data-type=uint8
        VOUTP_CRVentENSet_enum: implementation-data-type=uint8
        VOUTP_LEVentModeStaSet123_enum: implementation-data-type=uint8
        VOUTP_LEVentModeStaSet457_enum: implementation-data-type=uint8
        VOUTP_REVentModeStaSet123_enum: implementation-data-type=uint8
        VOUTP_REVentModeStaSet457_enum: implementation-data-type=uint8
        VOUTP_FDCTHCLEVentZStaSet{1..5}_enum: implementation-data-type=uint8
        VOUTP_FDCTHCLEVentZStaSet7_enum: implementation-data-type=uint8
        VOUTP_FDCTHCCLEVentZStaSet{1..5}_enum: implementation-data-type=uint8
        VOUTP_FDCTHCCLEVentZStaSet7_enum: implementation-data-type=uint8
        VOUTP_FDCTHCREVentZStaSet{1..5}_enum: implementation-data-type=uint8
        VOUTP_FDCTHCREVentZStaSet7_enum: implementation-data-type=uint8
        VOUTP_FDCTHCCREVentZStaSet{1..5}_enum: implementation-data-type=uint8
        VOUTP_FDCTHCCREVentZStaSet7_enum: implementation-data-type=uint8
        VOUTP_FDCTHCLEVentYStaSet{1..5}_enum: implementation-data-type=uint8
        VOUTP_FDCTHCLEVentYStaSet7_enum: implementation-data-type=uint8
        VOUTP_FDCTHCCLEVentYStaSet{1..5}_enum: implementation-data-type=uint8
        VOUTP_FDCTHCCLEVentYStaSet7_enum: implementation-data-type=uint8
        VOUTP_FDCTHCREVentYStaSet{1..5}_enum: implementation-data-type=uint8
        VOUTP_FDCTHCREVentYStaSet7_enum: implementation-data-type=uint8
        VOUTP_FDCTHCCREVentYStaSet{1..5}_enum: implementation-data-type=uint8
        VOUTP_FDCTHCCREVentYStaSet7_enum: implementation-data-type=uint8
        VOUTP_SettempZon1Set{1..5}_enum: implementation-data-type=uint8
        VOUTP_SettempZon1Set7_enum: implementation-data-type=uint8
        VOUTP_ACModeSet123_enum: implementation-data-type=uint8
        VOUTP_ACModeSet457_enum: implementation-data-type=uint8
        VOUTP_FACESet_enum: implementation-data-type=uint8
        VOUTP_FOOTSet_enum: implementation-data-type=uint8
        VOUTP_FrostSet_enum: implementation-data-type=uint8
        VOUTP_LVentEN_flg: implementation-data-type=boolean
        VOUTP_CLVentEN_flg: implementation-data-type=boolean
        VOUTP_RVentEN_flg: implementation-data-type=boolean
        VOUTP_CRVentEN_flg: implementation-data-type=boolean
        VOUTP_FDCFGSLearnCmd_enum: implementation-data-type=uint8
        VOUTP_FDCFGSFuncSta_flg: implementation-data-type=boolean
        VOUTP_THSysErrlampReq_flg: implementation-data-type=boolean
        VOUTP_LFBatWarn_flg: implementation-data-type=boolean
        VOUTP_RFBatWarn_flg: implementation-data-type=boolean
        VOUTP_LRBatWarn_flg: implementation-data-type=boolean
        VOUTP_RRBatWarn_flg: implementation-data-type=boolean
        VOUTP_LFWheelPress_raw8: implementation-data-type=uint8
        VOUTP_RFWheelPress_raw8: implementation-data-type=uint8
        VOUTP_LRWheelPress_raw8: implementation-data-type=uint8
        VOUTP_RRWheelPress_raw8: implementation-data-type=uint8
        VOUTP_LFWheelTemp_C: implementation-data-type=float32
        VOUTP_RFWheelTemp_C: implementation-data-type=float32
        VOUTP_LRWheelTemp_C: implementation-data-type=float32
        VOUTP_RRWheelTemp_C: implementation-data-type=float32
        VOUTP_LFSensorFail_flg: implementation-data-type=boolean
        VOUTP_RFSensorFail_flg: implementation-data-type=boolean
        VOUTP_LRSensorFail_flg: implementation-data-type=boolean
        VOUTP_RRSensorFail_flg: implementation-data-type=boolean
        VOUTP_LFWheelDebug_flg: implementation-data-type=boolean
        VOUTP_LRWheelDebug_flg: implementation-data-type=boolean
        VOUTP_RFWheelDebug_flg: implementation-data-type=boolean
        VOUTP_RRWheelDebug_flg: implementation-data-type=boolean
        VOUTP_TPMSResButtAllow_flg: implementation-data-type=boolean
        VOUTP_TPMSCaliButtAllow_flg: implementation-data-type=boolean
        VOUTP_LFPressIndi_enum: implementation-data-type=uint8
        VOUTP_RFPressIndi_enum: implementation-data-type=uint8
        VOUTP_LRPressIndi_enum: implementation-data-type=uint8
        VOUTP_RRPressIndi_enum: implementation-data-type=uint8
        VOUTP_TPMSWarnIndi_enum: implementation-data-type=uint8
        VOUTP_LFWheelTmpIndi_flg: implementation-data-type=boolean
        VOUTP_RFWheelTmpIndi_flg: implementation-data-type=boolean
        VOUTP_LRWheelTmpIndi_flg: implementation-data-type=boolean
        VOUTP_RRWheelTmpIndi_flg: implementation-data-type=boolean
        VOUTP_LFWheelPSW_raw8: implementation-data-type=uint8
        VOUTP_LRWheelPSW_raw8: implementation-data-type=uint8
        VOUTP_RFWheelPSW_raw8: implementation-data-type=uint8
        VOUTP_RRWheelPSW_raw8: implementation-data-type=uint8
        VOUTP_CWheelTips_enum: implementation-data-type=uint8
        VOUTP_AutoLTips_enum: implementation-data-type=uint8
        VOUTP_LFSensorMode_flg: implementation-data-type=boolean
        VOUTP_RFSensorMode_flg: implementation-data-type=boolean
        VOUTP_LRSensorMode_flg: implementation-data-type=boolean
        VOUTP_RRSensorMode_flg: implementation-data-type=boolean
        VOUTP_S{1..4}ID_raw32: implementation-data-type=uint32
        VOUTP_S{1..4}L_enum: implementation-data-type=uint8
        VOUTP_ALFin_flg: implementation-data-type=boolean
        VOUTP_LFP20_raw8: implementation-data-type=uint8
        VOUTP_RFP20_raw8: implementation-data-type=uint8
        VOUTP_LRP20_raw8: implementation-data-type=uint8
        VOUTP_RRP20_raw8: implementation-data-type=uint8
        VOUTP_FAT_flg: implementation-data-type=boolean
        VOUTP_IDin_raw32: implementation-data-type=uint32
        VOUTP_S{1..4}WheelDebugALTU_pct: implementation-data-type=float32
        VOUTP_ID{1..4}messageALTU_raw8: implementation-data-type=uint8
        VOUTP_Chkfin_flg: implementation-data-type=boolean
        VOUTP_SetIDLoc_flg: implementation-data-type=boolean
        VOUTP_TPMSStorge_flg: implementation-data-type=boolean
        VOUTP_ChkStorge_flg: implementation-data-type=boolean
        VOUTP_TPMSResButt_flg: implementation-data-type=boolean
        VOUTP_LFPindi_enum: implementation-data-type=uint8
        VOUTP_RFPind_enum: implementation-data-type=uint8
        VOUTP_LRPindi_enum: implementation-data-type=uint8
        VOUTP_RRPindi_enum: implementation-data-type=uint8
        VOUTP_WriteChkLFID_raw: implementation-data-type=uint32
        VOUTP_WriteChkRFID_raw: implementation-data-type=uint32
        VOUTP_WriteChkLRID_raw: implementation-data-type=uint32
        VOUTP_WriteChkRRID_raw: implementation-data-type=uint32
        VOUTP_WriteChkfinLFID_raw: implementation-data-type=uint32
        VOUTP_WriteChkfinRFID_raw: implementation-data-type=uint32
        VOUTP_WriteChkfinLRID_raw: implementation-data-type=uint32
        VOUTP_WriteChkfinRRID_raw: implementation-data-type=uint32
        VOUTP_Flashchkdatavalid_enum: implementation-data-type=uint8
        VOUTP_Flashdatavalid_enum: implementation-data-type=uint8
        VOUTP_unlearnSfali_flg: implementation-data-type=boolean
        VOUTP_unlearnSfailvalid_enum: implementation-data-type=uint8
        VOUTP_Prepresstempvalid_enum: implementation-data-type=uint8
        VOUTP_FlashS{1..4}ID_raw: implementation-data-type=uint32
        VOUTP_FlashIDvalid_enum: implementation-data-type=uint8
        VOUTP_WritingCnt_enum: implementation-data-type=uint8
        VOUTP_TPMSTLCmd_flg: implementation-data-type=boolean
        VOUTP_LProgress_enum: implementation-data-type=uint8
        VOUTP_TPMSSensorIDRegStart_flg: implementation-data-type=boolean
        VOUTP_ModelVersion_raw: implementation-data-type=uint8
        VOUTP_ModelVersionChksum_raw: implementation-data-type=uint8
        VOUTP_ParkRequest_flg: implementation-data-type=boolean
        VOUTP_TqSourceFr_enum: implementation-data-type=uint8
        VOUTP_TqSourceRr_enum: implementation-data-type=uint8
        VOUTP_FrEDUAvailBrkRgnTq_Nm: implementation-data-type=float32
        VOUTP_RrEDUAvailBrkRgnTq_Nm: implementation-data-type=float32
        VOUTP_EVDriveMode_enum: implementation-data-type=uint8
        VOUTP_ShiftGearPosn_enum: implementation-data-type=uint8
        VOUTP_PButtonSta_enum: implementation-data-type=uint8
        VOUTP_FrActvDmpDisabReq_flg: implementation-data-type=boolean
        VOUTP_RrActvDmpDisabReq_flg: implementation-data-type=boolean
        VOUTP_FrRgnDecrSta_flg: implementation-data-type=boolean
        VOUTP_RrRgnDecrSta_flg: implementation-data-type=boolean
        VOUTP_DriverWhlTqDemFr_Nm: implementation-data-type=float32
        VOUTP_DriverWhlTqDemRr_Nm: implementation-data-type=float32
        VOUTP_FrEDUActTq_Nm: implementation-data-type=float32
        VOUTP_RrEDUActTq_Nm: implementation-data-type=float32
        VOUTP_FrEDURolRgnTq_Nm: implementation-data-type=float32
        VOUTP_RrEDURolRgnTq_Nm: implementation-data-type=float32
        VOUTP_FrEDUSpd_rpm: implementation-data-type=float32
        VOUTP_RrEDUSpd_rpm: implementation-data-type=float32
        VOUTP_FrEDUSpdValid_flg: implementation-data-type=boolean
        VOUTP_FrEDUAvailBrkRgnTqV_flg: implementation-data-type=boolean
        VOUTP_RrEDUSpdValid_flg: implementation-data-type=boolean
        VOUTP_RrEDUAvailBrkRgnTqV_flg: implementation-data-type=boolean
        VOUTP_RgnAbnorSta_flg: implementation-data-type=boolean
        VOUTP_PTCSPermSta_flg: implementation-data-type=boolean
        VOUTP_FrRgnPermSta_flg: implementation-data-type=boolean
        VOUTP_RrRgnPermSta_flg: implementation-data-type=boolean
        VOUTP_FrIdcMin_A: implementation-data-type=float32
        VOUTP_FrIdcMax_A: implementation-data-type=float32
        VOUTP_FrUdcMin_V: implementation-data-type=float32
        VOUTP_FrUdcMax_V: implementation-data-type=float32
        VOUTP_RrIdcMin_A: implementation-data-type=float32
        VOUTP_RrIdcMax_A: implementation-data-type=float32
        VOUTP_RrUdcMin_V: implementation-data-type=float32
        VOUTP_RrUdcMax_V: implementation-data-type=float32
        VOUTP_ReBrakeLPReq_flg: implementation-data-type=boolean
        VOUTP_BOSEnable_flg: implementation-data-type=boolean
        VOUTP_CreepON_flg: implementation-data-type=boolean
        VOUTP_RDCActive_enum: implementation-data-type=uint8
        VOUTP_EquivAccPedalSWSta_flg: implementation-data-type=boolean
        VOUTP_DriveProtEn_flg: implementation-data-type=boolean
        VOUTP_ActParkRequest_flg: implementation-data-type=boolean
        VOUTP_RegenTqLimitEn_flg: implementation-data-type=boolean
        VOUTP_IVIPwrLockSta_enum: implementation-data-type=uint8
        VOUTP_OPDHoldLamp_flg: implementation-data-type=boolean
        VOUTP_SaveRegenMode_enum: implementation-data-type=uint8
        VOUTP_FDCVCURegenMode_enum: implementation-data-type=uint8
        VOUTP_SpdCtrlMode_enum: implementation-data-type=uint8
        VOUTP_SpdCtrlSta_flg: implementation-data-type=boolean
        VOUTP_SetSpd_kph: implementation-data-type=float32
        VOUTP_VehActSpd_kph: implementation-data-type=float32
        VOUTP_RegenLimIndSta_flg: implementation-data-type=boolean
        VOUTP_SetSpdLimWarn_flg: implementation-data-type=boolean
        VOUTP_MaxWhlSlideRate_pct: implementation-data-type=float32
        VOUTP_TrailerDisOPDSta_flg: implementation-data-type=boolean
        VOUTP_ForceP_flg: implementation-data-type=boolean
        VOUTP_SlideRegenLimTq_Nm: implementation-data-type=float32
        VOUTP_SimSoundCmd_pct: implementation-data-type=float32
        VOUTP_SimSouWaveReq_pct: implementation-data-type=float32
        VOUTP_FrTMTqReq_Nm: implementation-data-type=float32
        VOUTP_RrTMTqReq_Nm: implementation-data-type=float32
        VOUTP_FrFirstOrderInpTs_c: implementation-data-type=float32
        VOUTP_RrFirstOrderInpTs_c: implementation-data-type=float32
        VOUTP_FrRateLimitInc_Nm: implementation-data-type=float32
        VOUTP_FrRateLimitDec_Nm: implementation-data-type=float32
        VOUTP_RrRateLimitInc_Nm: implementation-data-type=float32
        VOUTP_RrRateLimitDec_Nm: implementation-data-type=float32
        VOUTP_ReqOBCV2LEna_enum: implementation-data-type=uint8
        VOUTP_ReqV2LIVIPopup_enum: implementation-data-type=uint8
        VOUTP_ReqV2LIVIDisChrg_enum: implementation-data-type=uint8
        VOUTP_ReqOBCExtrV2LEna_enum: implementation-data-type=uint8
        VOUTP_ReqOBCIntrV2LEna_enum: implementation-data-type=uint8
        VOUTP_HVPO120VGrpALDSt_enum: implementation-data-type=uint8
        VOUTP_HVPO120VGrpBLDSt_enum: implementation-data-type=uint8
        VOUTP_FeatSetSpdFinal_raw32: implementation-data-type=float32
        VOUTP_VehicleSpeed_mph: implementation-data-type=float32
        VOUTP_VehicleSpeed_kph: implementation-data-type=float32
        VOUTP_MeterIndSpeed_raw32: implementation-data-type=float32
        VOUTP_VMCAEBCtrlAvail_flg: implementation-data-type=boolean
        VOUTP_VMCACCCtrlAvail_flg: implementation-data-type=boolean
        VOUTP_VMCCCCtrlAvail_flg: implementation-data-type=boolean
        VOUTP_VMCMSACtrlAvail_flg: implementation-data-type=boolean
        VOUTP_FeatArbitrSta_enum: implementation-data-type=uint8
        VOUTP_FeatReqSpd_kph: implementation-data-type=float32
        VOUTP_JerkPCT_pct: implementation-data-type=float32
        VOUTP_LimitPCT_pct: implementation-data-type=float32
        VOUTP_FrontRearSlipRatioCtrl_flg: implementation-data-type=boolean
        VOUTP_RearWhlSlipRatioCtrl_flg: implementation-data-type=boolean
        VOUTP_SingleWhlSlipRatioCtrl_flg: implementation-data-type=boolean
        VOUTP_LatAccCtrl_flg: implementation-data-type=boolean
        VOUTP_SafetyCtrl_flg: implementation-data-type=boolean
        VOUTP_SPD2ACCAct_flg: implementation-data-type=boolean
        VOUTP_AccCalcuPID_mps2: implementation-data-type=float32
        VOUTP_ISOAccLimit_mps2: implementation-data-type=float32
        VOUTP_ISODecLimit_mps2: implementation-data-type=float32
        VOUTP_ISOJerkLimit_mps3: implementation-data-type=float32
        VOUTP_ACCRequiredAccel_mps2: implementation-data-type=float32
        VOUTP_DISCReqAcc_mps2: implementation-data-type=float32
        VOUTP_FeatArbitrFinal_enum: implementation-data-type=uint8
        VOUTP_ActACCRequiredAccel_mps2: implementation-data-type=float32
        VOUTP_LateralCtrl_flg: implementation-data-type=boolean
        VOUTP_ADASLKASta_enum: implementation-data-type=uint8
        VOUTP_LKAStrToqReq_Nm: implementation-data-type=float32
        VOUTP_LKATOIFault_flg: implementation-data-type=boolean
        VOUTP_LKATOIAct_enum: implementation-data-type=uint8
        VOUTP_ADASAEBReq_enum: implementation-data-type=uint8
        VOUTP_ADASFaultSta_flg: implementation-data-type=boolean
        VOUTP_AEBVehHoldReq_flg: implementation-data-type=boolean
        VOUTP_ACCVehHoldReq_flg: implementation-data-type=boolean
        VOUTP_ADASDBSReq_enum: implementation-data-type=uint8
        VOUTP_ADASACCSta_enum: implementation-data-type=uint8
        VOUTP_ACCObjDist_m: implementation-data-type=float32
        VOUTP_ACCObjRelSpd_mps: implementation-data-type=float32
        VOUTP_TimeGapLevel_enum: implementation-data-type=uint8
        VOUTP_ACCJerkUpperLimit_mps3: implementation-data-type=float32
        VOUTP_ACCComfortBandUpper_mps2: implementation-data-type=float32
        VOUTP_ACCJerkLowerLimit_mps3: implementation-data-type=float32
        VOUTP_ACCComfortBandLower_mps2: implementation-data-type=float32
        VOUTP_ADASVehSpdLim_raw32: implementation-data-type=float32
        VOUTP_ADASShftPosnReqA_flg: implementation-data-type=boolean
        VOUTP_ADASShftPosnReq_enum: implementation-data-type=uint8
        VOUTP_ADASForceIdle_flg: implementation-data-type=boolean
        VOUTP_HazardWarningReq_flg: implementation-data-type=boolean
        VOUTP_RightTurnLightReq_flg: implementation-data-type=boolean
        VOUTP_LeftTurnLightReq_flg: implementation-data-type=boolean
        VOUTP_ADASFCWSta_enum: implementation-data-type=uint8
        VOUTP_ADASLDWSta_enum: implementation-data-type=uint8
        VOUTP_ADASFltWrnReq_flg: implementation-data-type=boolean
        VOUTP_ACCObjDstLvl_enum: implementation-data-type=uint8
        VOUTP_ForceLowBeam_enum: implementation-data-type=uint8
        VOUTP_ACCTakeoverReq_flg: implementation-data-type=boolean
        VOUTP_ADASWarningMsg_enum: implementation-data-type=uint8
        VOUTP_ADASCAMSpdLim_enum: implementation-data-type=uint8
        VOUTP_TargetType_enum: implementation-data-type=uint8
        VOUTP_ADASSLIFSpdLim_enum: implementation-data-type=uint8
        VOUTP_LKAHODDisplayWarning_flg: implementation-data-type=boolean
        VOUTP_LKAHODSoundWarning_flg: implementation-data-type=boolean
        VOUTP_ADASLFCSta_enum: implementation-data-type=uint8
        VOUTP_ADASLaneModeL_enum: implementation-data-type=uint8
        VOUTP_ADASLaneModeR_enum: implementation-data-type=uint8
        VOUTP_ADASSLIFSta_enum: implementation-data-type=uint8
        VOUTP_ADASISASta_enum: implementation-data-type=uint8
        VOUTP_ADASLDWMute_flg: implementation-data-type=boolean
        VOUTP_ADASFCWMute_flg: implementation-data-type=boolean
        VOUTP_ADASLFCHandsOffWarning_enum: implementation-data-type=uint8
        VOUTP_LVDADisabled_flg: implementation-data-type=boolean
        VOUTP_LVDAMuteSta_enum: implementation-data-type=uint8
        VOUTP_LVDAFailinfo_flg: implementation-data-type=boolean
        VOUTP_LVDAWarning_flg: implementation-data-type=boolean
        VOUTP_LVDAACCStatusInformation_flg: implementation-data-type=boolean
        VOUTP_ADASLFCWarnSound_enum: implementation-data-type=uint8
        VOUTP_FCMACCmode_enum: implementation-data-type=uint8
        VOUTP_ADASLanetypeR_enum: implementation-data-type=uint8
        VOUTP_ADASLanetypeL_enum: implementation-data-type=uint8
        VOUTP_ADASLanecurveL_raw32: implementation-data-type=float32
        VOUTP_ADASLanecurveR_raw32: implementation-data-type=float32
        VOUTP_ADASAEBSta_enum: implementation-data-type=uint8
        VOUTP_FCMLDWRequest_enum: implementation-data-type=uint8
        VOUTP_FCMLDWFault_flg: implementation-data-type=boolean
        VOUTP_ACCCtrlAvail_flg: implementation-data-type=boolean
        VOUTP_ACCPedalOvrd_flg: implementation-data-type=boolean
        VOUTP_TimeGapCalcu_s: implementation-data-type=float32
        VOUTP_CCCtrlSta_enum: implementation-data-type=uint8
        VOUTP_MSACtrlSta_enum: implementation-data-type=uint8
        VOUTP_APSCtrlAvail_flg: implementation-data-type=boolean
        VOUTP_APSActive_flg: implementation-data-type=boolean
        VOUTP_APSStaSys_enum: implementation-data-type=uint8
        VOUTP_APSDecReqA_flg: implementation-data-type=boolean
        VOUTP_APSDecReq_mps2: implementation-data-type=float32
        VOUTP_APSReq_enum: implementation-data-type=uint8
        VOUTP_LongAcc_Gps: implementation-data-type=float32
        VOUTP_CCMSASpdWar_flg: implementation-data-type=boolean
        VOUTP_IMUEnaCmd_flg: implementation-data-type=boolean
        VOUTP_ActStESCYaw_Dps: implementation-data-type=float32
        VOUTP_CAASCtrlAvail_flg: implementation-data-type=boolean
        VOUTP_CAASActive_flg: implementation-data-type=boolean
        VOUTP_ExtraMSACtrlSta_enum: implementation-data-type=uint8
        VOUTP_CalibratedAccX_G: implementation-data-type=float32
        VOUTP_CalibratedAccY_G: implementation-data-type=float32
        VOUTP_CalibratedAccZ_G: implementation-data-type=float32
        VOUTP_CalibratedGyroX_Dps: implementation-data-type=float32
        VOUTP_CalibratedGyroY_Dps: implementation-data-type=float32
        VOUTP_CalibratedGyroZ_Dps: implementation-data-type=float32
        VOUTP_FDCVMCAPSVRqEPSCtrl_flg: implementation-data-type=boolean
        VOUTP_FDCVMCAPSAngleTarget_deg: implementation-data-type=float32
        VOUTP_FDCVMCAPSRqEPSCtrl_flg: implementation-data-type=boolean
        VOUTP_FDCVMCAngCtrlTqWtGn_pct: implementation-data-type=float32
        VOUTP_FDCVMCDrInpTqBstAct_flg: implementation-data-type=boolean
        VOUTP_FDCVMCMaxAngCtrlOutTqLim_Nm: implementation-data-type=float32
        VOUTP_FDCVMCDrInpTqBstGn_pct: implementation-data-type=float32
        VOUTP_VehPitchAngleSta_enum: implementation-data-type=uint8
        VOUTP_DMSModeCmd_enum: implementation-data-type=uint8
    u8_Array16_type: category=ARRAY
      element u8_Array16: category=VALUE, array-size=16, array-size-semantics=FIXED-SIZE, base-type=uint8
    u8_Array8_type: category=ARRAY
      element u8_Array8: category=VALUE, array-size=8, array-size-semantics=FIXED-SIZE, base-type=uint8
    u16_Array8_type: category=ARRAY
      element u16_Array8: category=VALUE, array-size=8, array-size-semantics=FIXED-SIZE, base-type=uint16
    u32_Array8_type: category=ARRAY
      element u32_Array8: category=VALUE, array-size=8, array-size-semantics=FIXED-SIZE, base-type=uint32
    u8_Array17_type: category=ARRAY
      element u8_Array17: category=VALUE, array-size=17, array-size-semantics=FIXED-SIZE, base-type=uint8
package /Impl_Type_OUTP2_ARPkg
  impl type BOUTP2_outputs: category=STRUCTURE
    89 x element, all with category=TYPE_REFERENCE:
      VOUTP_PowerSta_enum: implementation-data-type=uint8
      VOUTP_BrkPedalPos_pct: implementation-data-type=float32
      VOUTP_ActAPSPosn_pct: implementation-data-type=float32
      VOUTP_LFRawWhlSpeed_kph: implementation-data-type=float32
      VOUTP_RFRawWhlSpeed_kph: implementation-data-type=float32
      VOUTP_LRRawWhlSpeed_kph: implementation-data-type=float32
      VOUTP_RRRawWhlSpeed_kph: implementation-data-type=float32
      VOUTP_LFRawWhlSpeedV_flg: implementation-data-type=boolean
      VOUTP_RFRawWhlSpeedV_flg: implementation-data-type=boolean
      VOUTP_LRRawWhlSpeedV_flg: implementation-data-type=boolean
      VOUTP_RRRawWhlSpeedV_flg: implementation-data-type=boolean
      VOUTP_LFWhlRotDir_enum: implementation-data-type=uint8
      VOUTP_RFWhlRotDir_enum: implementation-data-type=uint8
      VOUTP_LRWhlRotDir_enum: implementation-data-type=uint8
      VOUTP_RRWhlRotDir_enum: implementation-data-type=uint8
      VOUTP_LFPulseCountV_flg: implementation-data-type=boolean
      VOUTP_RFPulseCountV_flg: implementation-data-type=boolean
      VOUTP_LRPulseCountV_flg: implementation-data-type=boolean
      VOUTP_RRPulseCountV_flg: implementation-data-type=boolean
      VOUTP_LFPulseCount_enum: implementation-data-type=uint8
      VOUTP_RFPulseCount_enum: implementation-data-type=uint8
      VOUTP_LRPulseCount_enum: implementation-data-type=uint8
      VOUTP_RRPulseCount_enum: implementation-data-type=uint8
      VOUTP_VehSpeed_kph: implementation-data-type=float32
      VOUTP_APSCtrlAvail_flg: implementation-data-type=boolean
      VOUTP_ShifterHandleCmd_enum: implementation-data-type=uint8
      VOUTP_DriIntend_enum: implementation-data-type=uint8
      VOUTP_EPSAOIControl_enum: implementation-data-type=uint8
      VOUTP_SASAngle_Deg: implementation-data-type=float32
      VOUTP_SASSpeed_degps: implementation-data-type=float32
      VOUTP_SASSpeedValid_flg: implementation-data-type=boolean
      VOUTP_SASCAL_flg: implementation-data-type=boolean
      VOUTP_SASV_flg: implementation-data-type=boolean
      VOUTP_GRADE_Deg: implementation-data-type=float32
      VOUTP_YawRate_degps: implementation-data-type=float32
      VOUTP_LatAccel_Gps: implementation-data-type=float32
      VOUTP_LongAccel_Gps: implementation-data-type=float32
      VOUTP_MCPressure_bar: implementation-data-type=float32
      VOUTP_YawRateV_flg: implementation-data-type=boolean
      VOUTP_LatAccelV_flg: implementation-data-type=boolean
      VOUTP_LongAccelV_flg: implementation-data-type=boolean
      VOUTP_MCPressureV_bar: implementation-data-type=boolean
      VOUTP_BrkSwSta_flg: implementation-data-type=boolean
      VOUTP_BrkSwV_flg: implementation-data-type=boolean
      VOUTP_ESCStandstill_flg: implementation-data-type=boolean
      VOUTP_ESCAPSSta_enum: implementation-data-type=uint8
      VOUTP_EPBExtReleaseAvail_flg: implementation-data-type=boolean
      VOUTP_EPBExtApplyAvail_flg: implementation-data-type=boolean
      VOUTP_EPBErrSta_enum: implementation-data-type=uint8
      VOUTP_EPBSta_enum: implementation-data-type=uint8
      VOUTP_AllDoorSW_flg: implementation-data-type=boolean
      VOUTP_HoodSW_flg: implementation-data-type=boolean
      VOUTP_TailgateSW_flg: implementation-data-type=boolean
      VOUTP_AVMparkingcancel_enum: implementation-data-type=uint8
      VOUTP_AVMparkingexcute_enum: implementation-data-type=uint8
      VOUTP_AVMParkingmode_enum: implementation-data-type=uint8
      VOUTP_AVMErrSTA_flg: implementation-data-type=boolean
      VOUTP_IVIStatus_flg: implementation-data-type=boolean
      VOUTP_CAASSw_enum: implementation-data-type=uint8
      VOUTP_IVIScreen_enum: implementation-data-type=uint8
      VOUTP_ABSActive_flg: implementation-data-type=boolean
      VOUTP_TCSActive_flg: implementation-data-type=boolean
      VOUTP_DriverSeatBeltCmd_flg: implementation-data-type=boolean
      VOUTP_DrDoorSW_flg: implementation-data-type=boolean
      VOUTP_PsDoorSW_flg: implementation-data-type=boolean
      VOUTP_RLDoorSW_flg: implementation-data-type=boolean
      VOUTP_RRDoorSW_flg: implementation-data-type=boolean
      VOUTP_RFPressIndi_enum: implementation-data-type=uint8
      VOUTP_LFPressIndi_enum: implementation-data-type=uint8
      VOUTP_RRPressIndi_enum: implementation-data-type=uint8
      VOUTP_LRPressIndi_enum: implementation-data-type=uint8
      VOUTP_sigAmbAirT_C: implementation-data-type=float32
      VOUTP_DrSeatSta_enum: implementation-data-type=uint8
      VOUTP_IVIUserTakeOverAPSSta_flg: implementation-data-type=boolean
      VOUTP_ShiftGearPosn_enum: implementation-data-type=uint8
      VOUTP_FSOffSw_enum: implementation-data-type=uint8
      VOUTP_VehSpeedTimeOut_flg: implementation-data-type=boolean
      VOUTP_FSOffSwTimeOut_flg: implementation-data-type=boolean
      VOUTP_ChrgPlugSta_enum: implementation-data-type=uint8
      VOUTP_VCURAPSErrLv2_flg: implementation-data-type=boolean
      VOUTP_VCURAPSErrLv3_flg: implementation-data-type=boolean
      VOUTP_PUIDLowPower_flg: implementation-data-type=boolean
      VOUTP_DKCParkingModeCmd_enum: implementation-data-type=uint8
      VOUTP_DKCPDkeyAreaRAPSSta_enum: implementation-data-type=uint8
      VOUTP_PwrReqRAPSAvail_flg: implementation-data-type=boolean
      VOUTP_CAASActive_flg: implementation-data-type=boolean
      VOUTP_VehActSpd_kph: implementation-data-type=float32
      VOUTP_CAASCtrlAvail_flg: implementation-data-type=boolean
      VOUTP_APSActive_flg: implementation-data-type=boolean
package /Interface_OUTP_ARPkg
  sender receiver interface IF_BOUTP_outputs
    data BOUTP_outputs: type=BOUTP_outputs
package /Interface_OUTP2_ARPkg
  sender receiver interface IF_BOUTP2_outputs
    data BOUTP2_outputs: type=BOUTP2_outputs
package /SWC_OUTP_ARPkg
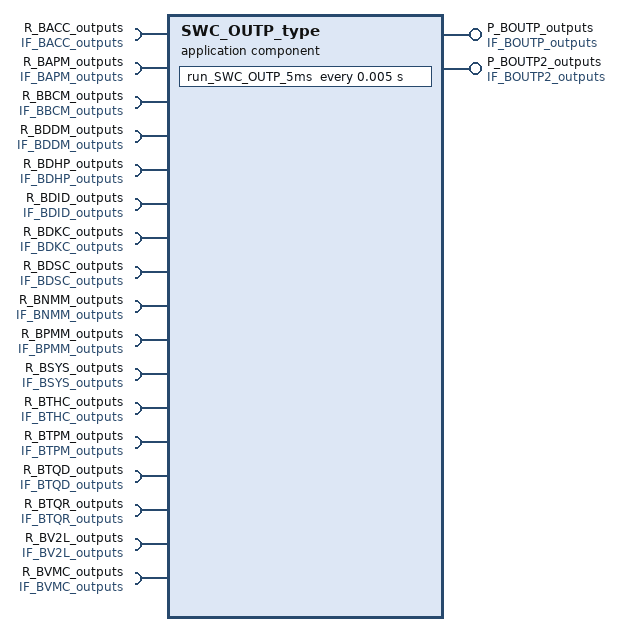
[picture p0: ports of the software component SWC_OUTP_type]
  application sw component type SWC_OUTP_type
    provide port P_BOUTP_outputs: provided-interface=IF_BOUTP_outputs
    provide port P_BOUTP2_outputs: provided-interface=IF_BOUTP2_outputs
    17 x require port:
      R_BACC_outputs: required-interface=IF_BACC_outputs
      R_BAPM_outputs: required-interface=IF_BAPM_outputs
      R_BBCM_outputs: required-interface=IF_BBCM_outputs
      R_BDDM_outputs: required-interface=IF_BDDM_outputs
      R_BDHP_outputs: required-interface=IF_BDHP_outputs
      R_BDID_outputs: required-interface=IF_BDID_outputs
      R_BDKC_outputs: required-interface=IF_BDKC_outputs
      R_BDSC_outputs: required-interface=IF_BDSC_outputs
      R_BNMM_outputs: required-interface=IF_BNMM_outputs
      R_BPMM_outputs: required-interface=IF_BPMM_outputs
      R_BSYS_outputs: required-interface=IF_BSYS_outputs
      R_BTHC_outputs: required-interface=IF_BTHC_outputs
      R_BTPM_outputs: required-interface=IF_BTPM_outputs
      R_BTQD_outputs: required-interface=IF_BTQD_outputs
      R_BTQR_outputs: required-interface=IF_BTQR_outputs
      R_BV2L_outputs: required-interface=IF_BV2L_outputs
      R_BVMC_outputs: required-interface=IF_BVMC_outputs
    behavior SWC_OUTP_type_IB: handle-termination-and-restart=NO-SUPPORT
      timing event TE_OUTP_5ms: start-on-event=run_SWC_OUTP_5ms, period=0.005
      runnable run_SWC_OUTP_5ms
        data-receive-point-by-arguments:
          17 x access:
            drparg_BACC_outputs: accessed-variable=R_BACC_outputs.BACC_outputs
            drparg_BAPM_outputs: accessed-variable=R_BAPM_outputs.BAPM_outputs
            drparg_BBCM_outputs: accessed-variable=R_BBCM_outputs.BBCM_outputs
            drparg_BDDM_outputs: accessed-variable=R_BDDM_outputs.BDDM_outputs
            drparg_BDHP_outputs: accessed-variable=R_BDHP_outputs.BDHP_outputs
            drparg_BDID_outputs: accessed-variable=R_BDID_outputs.BDID_outputs
            drparg_BDKC_outputs: accessed-variable=R_BDKC_outputs.BDKC_outputs
            drparg_BDSC_outputs: accessed-variable=R_BDSC_outputs.BDSC_outputs
            drparg_BNMM_outputs: accessed-variable=R_BNMM_outputs.BNMM_outputs
            drparg_BPMM_outputs: accessed-variable=R_BPMM_outputs.BPMM_outputs
            drparg_BSYS_outputs: accessed-variable=R_BSYS_outputs.BSYS_outputs
            drparg_BTHC_outputs: accessed-variable=R_BTHC_outputs.BTHC_outputs
            drparg_BTPM_outputs: accessed-variable=R_BTPM_outputs.BTPM_outputs
            drparg_BTQD_outputs: accessed-variable=R_BTQD_outputs.BTQD_outputs
            drparg_BTQR_outputs: accessed-variable=R_BTQR_outputs.BTQR_outputs
            drparg_BV2L_outputs: accessed-variable=R_BV2L_outputs.BV2L_outputs
            drparg_BVMC_outputs: accessed-variable=R_BVMC_outputs.BVMC_outputs
        data-send-points:
          access dsp_BOUTP_outputs: accessed-variable=P_BOUTP_outputs.BOUTP_outputs
          access dsp_BOUTP2_outputs: accessed-variable=P_BOUTP2_outputs.BOUTP2_outputs
